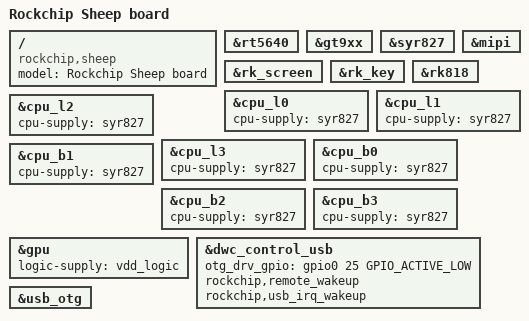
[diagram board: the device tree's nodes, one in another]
/*
 * Copyright (c) 2015 Fuzhou Rockchip Electronics Co., Ltd
 *
 * This file is dual-licensed: you can use it either under the terms
 * of the GPL or the X11 license, at your option. Note that this dual
 * licensing only applies to this file, and not this project as a
 * whole.
 *
 *  a) This file is free software; you can redistribute it and/or
 *     modify it under the terms of the GNU General Public License as
 *     published by the Free Software Foundation; either version 2 of the
 *     License, or (at your option) any later version.
 *
 *     This file is distributed in the hope that it will be useful,
 *     but WITHOUT ANY WARRANTY; without even the implied warranty of
 *     MERCHANTABILITY or FITNESS FOR A PARTICULAR PURPOSE.  See the
 *     GNU General Public License for more details.
 *
 * Or, alternatively,
 *
 *  b) Permission is hereby granted, free of charge, to any person
 *     obtaining a copy of this software and associated documentation
 *     files (the "Software"), to deal in the Software without
 *     restriction, including without limitation the rights to use,
 *     copy, modify, merge, publish, distribute, sublicense, and/or
 *     sell copies of the Software, and to permit persons to whom the
 *     Software is furnished to do so, subject to the following
 *     conditions:
 *
 *     The above copyright notice and this permission notice shall be
 *     included in all copies or substantial portions of the Software.
 *
 *     THE SOFTWARE IS PROVIDED "AS IS", WITHOUT WARRANTY OF ANY KIND,
 *     EXPRESS OR IMPLIED, INCLUDING BUT NOT LIMITED TO THE WARRANTIES
 *     OF MERCHANTABILITY, FITNESS FOR A PARTICULAR PURPOSE AND
 *     NONINFRINGEMENT. IN NO EVENT SHALL THE AUTHORS OR COPYRIGHT
 *     HOLDERS BE LIABLE FOR ANY CLAIM, DAMAGES OR OTHER LIABILITY,
 *     WHETHER IN AN ACTION OF CONTRACT, TORT OR OTHERWISE, ARISING
 *     FROM, OUT OF OR IN CONNECTION WITH THE SOFTWARE OR THE USE OR
 *     OTHER DEALINGS IN THE SOFTWARE.
 */

/dts-v1/;
#include "rk3368-tb.dtsi"

/ {
	model = "Rockchip Sheep board";
	compatible = "rockchip,sheep", "rockchip,rk3368";
};

&rt5640 {
	status = "okay";
};

&gt9xx {
	status = "okay";
};

&syr827 {
	status = "okay";
};

&mipi {
	status = "okay";
};

&rk_screen {
	status = "okay";
	#include <dt-bindings/display/screen-timing/lcd-tv080wum-mipi.dtsi>
};

&rk_key {
	status = "okay";
};

&rk818 {
	status = "okay";
};

&cpu_l0 {
	cpu-supply = <&syr827>;
};

&cpu_l1 {
	cpu-supply = <&syr827>;
};

&cpu_l2 {
	cpu-supply = <&syr827>;
};

&cpu_l3 {
	cpu-supply = <&syr827>;
};

&cpu_b0 {
	cpu-supply = <&syr827>;
};

&cpu_b1 {
	cpu-supply = <&syr827>;
};

&cpu_b2 {
	cpu-supply = <&syr827>;
};

&cpu_b3 {
	cpu-supply = <&syr827>;
};

&gpu {
	logic-supply = <&vdd_logic>;
};

&dwc_control_usb {
	otg_drv_gpio = <&gpio0 25 GPIO_ACTIVE_LOW>;

	rockchip,remote_wakeup;
	rockchip,usb_irq_wakeup;
	status = "okay";
};

&usb_otg {
	status = "okay";
};
